# ADuCM410 register map
Vendor: Analog Devices; Series: ADuCM410; File version: 1p0
CPU: CM33 r0p1, little endian, MPU, FPU, 3 interrupt priority bits
Registers are 32-bit, read-write, reset 0x0 unless marked. A register's access mark holds for its fields unless they carry their own. Offsets are from the block's base; [hi:lo] are bit positions.

## DMA
Base 0x40040000
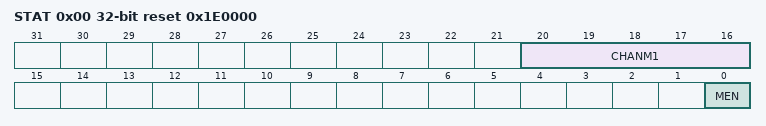
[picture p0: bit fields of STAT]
0x00 STAT reset 0x1E0000 — DMA Status
  [20:16] CHANM1 ro — Number of Available DMA Channels Minus 1
  [0] MEN ro — Enable Status of the Controller
0x04 CFG — DMA Configuration
  [0] MEN wo range 0x00000000..0x00000001 — Controller Enable
0x08 PDBPTR — DMA Channel Primary Control Data Base Pointer
  [31:0] ADDR range 0x00000000..0xFFFFFFFF — Pointer to the Base Address of the Primary Data Structure
0x0C ADBPTR reset 0x200 — DMA Channel Alternate Control Data Base Pointer
  [31:0] ADDR ro — Base Address of the Alternate Data Structure
0x14 SWREQ — DMA Channel Software Request
  [30:0] CHAN wo range 0x00000000..0x7FFFFFFF — Generate Software Request
0x20 RMSKSET — DMA Channel Request Mask Set
  [30:0] CHAN range 0x00000000..0x7FFFFFFF — Mask Requests from DMA Channels
0x24 RMSKCLR — DMA Channel Request Mask Clear
  [30:0] CHAN wo range 0x00000000..0x7FFFFFFF — Clear REQ_MASK_SET Bits in DMARMSKSET
0x28 ENSET — DMA Channel Enable Set
  [30:0] CHAN range 0x00000000..0x7FFFFFFF — Enable DMA Channels
0x2C ENCLR — DMA Channel Enable Clear
  [30:0] CHAN wo range 0x00000000..0x7FFFFFFF — Disable DMA Channels
0x30 ALTSET — DMA Channel Primary-alternate Set
  [30:0] CHAN range 0x00000000..0x7FFFFFFF — Control Structure Status / Select Alt Structure
0x34 ALTCLR — DMA Channel Primary-alternate Clear
  [30:0] CHAN wo range 0x00000000..0x7FFFFFFF — Select Primary Data Structure
0x38 PRISET — DMA Channel Priority Set
  [30:0] CHAN wo range 0x00000000..0x7FFFFFFF — Configure Channel for High Priority
0x3C PRICLR — DMA Channel Priority Clear
  [30:0] CHPRICLR wo range 0x00000000..0x7FFFFFFF — Configure Channel for Default Priority Level
0x48 ERRCHNLCLR — DMA per Channel Error Clear
  [30:0] CHAN range 0x00000000..0x7FFFFFFF — Per Channel Bus Error Status/ Clear
0x4C ERRCLR — DMA Bus Error Clear
  [30:0] CHAN range 0x00000000..0x7FFFFFFF — Bus Error Status
0x50 INVALIDDESCCLR — DMA per Channel Invalid Descriptor Clear
  [30:0] CHAN range 0x00000000..0x7FFFFFFF — Per Channel Invalid Descriptor Status
0x800 BSSET — DMA Channel Bytes Swap Enable Set
  [30:0] CHAN range 0x00000000..0x7FFFFFFF — Byte Swap Status
0x804 BSCLR — DMA Channel Bytes Swap Enable Clear
  [30:0] CHAN wo range 0x00000000..0x7FFFFFFF — Disable Byte Swap
0x810 SRCADDRSET — DMA Channel Source Address Decrement Enable Set
  [30:0] CHAN range 0x00000000..0x7FFFFFFF — Source Address Decrement Status / Configure
0x814 SRCADDRCLR — DMA Channel Source Address Decrement Enable Clear
  [30:0] CHAN wo range 0x00000000..0x7FFFFFFF — Disable Source Address Decrement
0x818 DSTADDRSET — DMA Channel Destination Address Decrement Enable Set
  [30:0] CHAN range 0x00000000..0x7FFFFFFF — Destination Address Decrement Status
0x81C DSTADDRCLR — DMA Channel Destination Address Decrement Enable Clear
  [30:0] CHAN wo range 0x00000000..0x7FFFFFFF — Disable Destination Address Decrement
0xFE0 REVID reset 0x2 — DMA Controller Revision ID
  [7:0] DMAREVID ro

## CACHE — Cache Controller
Base 0x40044000
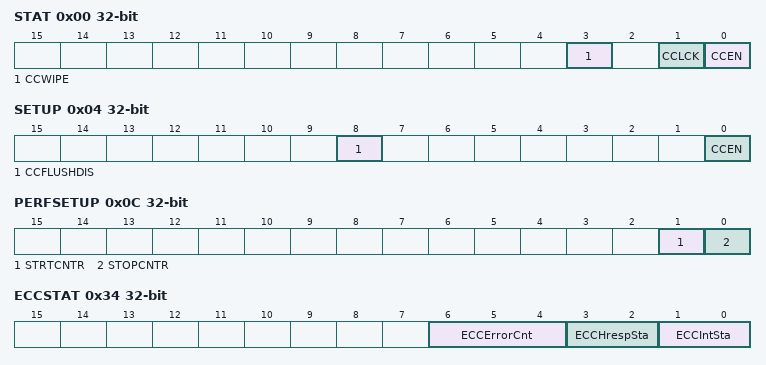
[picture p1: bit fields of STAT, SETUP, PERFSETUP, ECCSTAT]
0x00 STAT — Cache Status Register
  [3] CCWIPE ro — Code Cache Memory Wipe in Progress
  [1] CCLCK ro — Code Cache Lock Status
  [0] CCEN ro — Code Cache Enable Status
0x04 SETUP — Cache Setup Register
  [8] CCFLUSHDIS range 0x00000000..0x00000001 — Disable Automatic Cache and Buffer Flush on Any Flash Update
  [0] CCEN range 0x00000000..0x00000001 — Code Cache Enable
0x08 KEY — Cache Key Register
  [31:0] KEY wo range 0x00000000..0xFFFFFFFF
0x0C PERFSETUP — Cache Performance Monitor Setup Register
  [1] STRTCNTR wo range 0x00000000..0x00000001 — Performance Counter Start
  [0] STOPCNTR wo range 0x00000000..0x00000001 — Performance Counter Stop
0x10 ACCESSCNTR — Cache Miss Counter
  [31:0] CNT ro — Cache Internal Performance Counter
0x24 MSTRSETUP — Cache Master Setup Register
  [7:0] MSTRNRA range 0x00000000..0x000000FF — No Read Allocate for Master
0x34 ECCSTAT — Cache SRAM ECC Status Register
  [6:4] ECCErrorCnt ro — Cache SRAM ECC Error Counter
  [3:2] ECCHrespSta ro — Cache SRAM ECC Error Hresp Status
    0=NoError; 1=Error2bit (2 Bit Error); 2=Error1bit (1 Bit Error)
  [1:0] ECCIntSta ro — Cache SRAM ECC Error Interrupt Status
    0=NoError; 1=Error2bit (2 Bit Error); 2=Error1bit (1 Bit Error); 3=Error1or2bit (Either 1 Bit Error or 2 Bit Error)
0x38 ECCADDR — Cache SRAM ECC Address Register
  [10:0] ECCAddr ro — Cache SRAM ECC Error Interrupt Address
